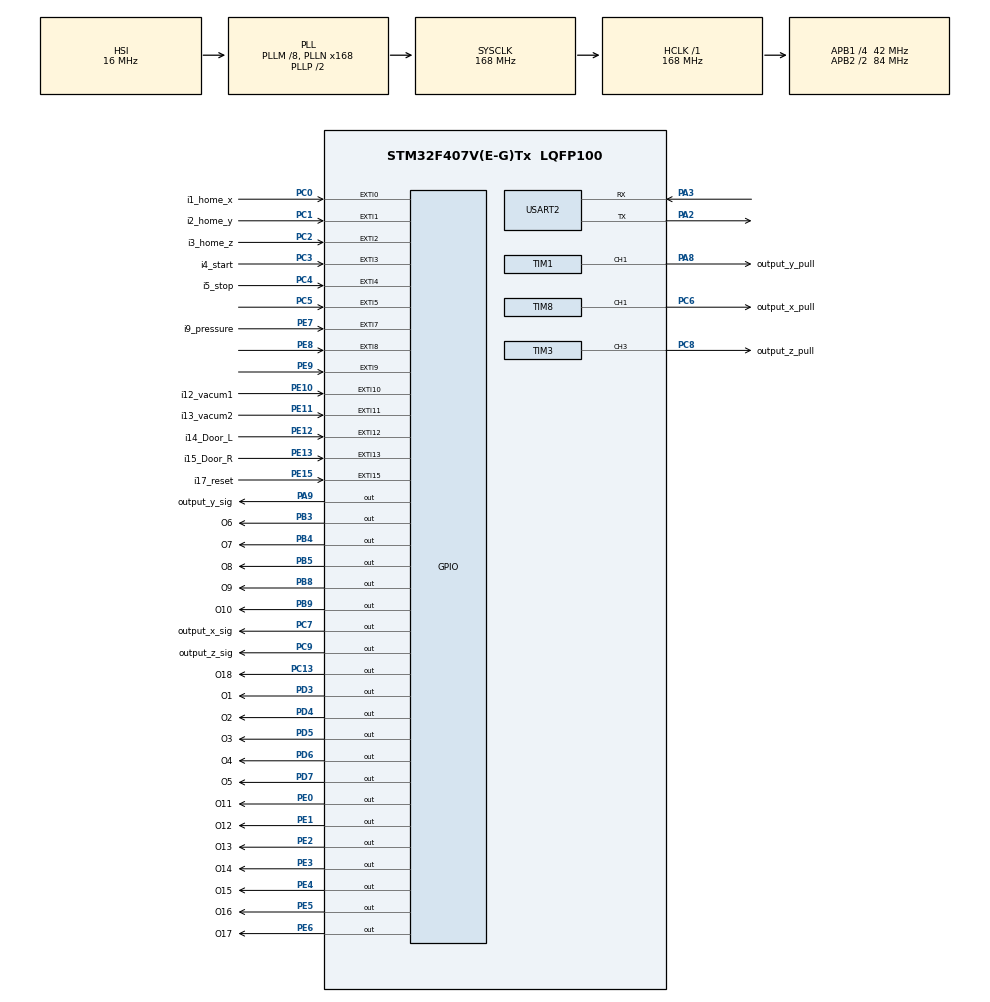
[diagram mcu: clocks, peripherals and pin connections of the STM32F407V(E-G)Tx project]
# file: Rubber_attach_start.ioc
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Dma.Request0=USART2_RX
Dma.USART2_RX.0.Direction=DMA_PERIPH_TO_MEMORY
Dma.USART2_RX.0.FIFOMode=DMA_FIFOMODE_DISABLE
Dma.USART2_RX.0.Instance=DMA1_Stream5
Dma.USART2_RX.0.MemDataAlignment=DMA_MDATAALIGN_BYTE
Dma.USART2_RX.0.MemInc=DMA_MINC_ENABLE
Dma.USART2_RX.0.Mode=DMA_NORMAL
Dma.USART2_RX.0.PeriphDataAlignment=DMA_PDATAALIGN_BYTE
Dma.USART2_RX.0.PeriphInc=DMA_PINC_DISABLE
Dma.USART2_RX.0.Priority=DMA_PRIORITY_LOW
Mcu.Family=STM32F4
Mcu.Name=STM32F407V(E-G)Tx
Mcu.Package=LQFP100
NVIC.DMA1_Stream5_IRQn=true\:0\:0\:false\:false\:true\:false\:true\:true
NVIC.EXTI0_IRQn=true\:10\:0\:true\:false\:true\:true\:true\:true
NVIC.EXTI15_10_IRQn=true\:4\:0\:true\:false\:true\:true\:true\:true
NVIC.EXTI1_IRQn=true\:10\:0\:true\:false\:true\:true\:true\:true
NVIC.EXTI2_IRQn=true\:10\:0\:true\:false\:true\:true\:true\:true
NVIC.EXTI3_IRQn=true\:3\:0\:true\:false\:true\:true\:true\:true
NVIC.EXTI4_IRQn=true\:1\:0\:true\:false\:true\:true\:true\:true
NVIC.EXTI9_5_IRQn=true\:2\:0\:true\:false\:true\:true\:true\:true
NVIC.PriorityGroup=NVIC_PRIORITYGROUP_4
NVIC.TIM1_BRK_TIM9_IRQn=true\:12\:0\:true\:false\:true\:true\:true\:true
NVIC.TIM2_IRQn=true\:12\:0\:true\:false\:true\:true\:true\:true
NVIC.TIM5_IRQn=true\:12\:0\:true\:false\:true\:true\:true\:true
NVIC.TIM6_DAC_IRQn=true\:15\:0\:true\:false\:true\:true\:true\:true
NVIC.TIM7_IRQn=true\:13\:0\:true\:false\:true\:true\:true\:true
NVIC.USART2_IRQn=true\:14\:0\:true\:false\:true\:true\:true\:true
PA13.Mode=Serial_Wire
PA13.Signal=SYS_JTMS-SWDIO
PA14.Mode=Serial_Wire
PA14.Signal=SYS_JTCK-SWCLK
PA2.Mode=Asynchronous
PA2.Signal=USART2_TX
PA3.Mode=Asynchronous
PA3.Signal=USART2_RX
PA8.GPIO_Label=output_y_pull
PA8.GPIO_PuPd=GPIO_PULLDOWN
PA8.GPIO_Speed=GPIO_SPEED_FREQ_VERY_HIGH
PA8.Signal=S_TIM1_CH1
PA9.GPIO_Label=output_y_sig
PA9.Signal=GPIO_Output
PB3.GPIO_Label=O6
PB3.Signal=GPIO_Output
PB4.GPIO_Label=O7
PB4.Signal=GPIO_Output
PB5.GPIO_Label=O8
PB5.Signal=GPIO_Output
PB8.GPIO_Label=O9
PB8.Signal=GPIO_Output
PB9.GPIO_Label=O10
PB9.PinState=GPIO_PIN_SET
PB9.Signal=GPIO_Output
PC0.GPIO_Label=i1_home_x
PC0.Signal=GPXTI0
PC1.GPIO_Label=i2_home_y
PC1.Signal=GPXTI1
PC13-ANTI_TAMP.GPIO_Label=O18
PC13-ANTI_TAMP.Signal=GPIO_Output
PC2.GPIO_Label=i3_home_z
PC2.Signal=GPXTI2
PC3.GPIO_Label=i4_start
PC3.Signal=GPXTI3
PC4.GPIO_Label=i5_stop
PC4.GPIO_ModeDefaultEXTI=GPIO_MODE_IT_RISING
PC4.Signal=GPXTI4
PC5.Signal=GPXTI5
PC6.GPIO_Label=output_x_pull
PC6.GPIO_PuPd=GPIO_PULLDOWN
PC6.GPIO_Speed=GPIO_SPEED_FREQ_VERY_HIGH
PC6.Signal=S_TIM8_CH1
PC7.GPIO_Label=output_x_sig
PC7.Signal=GPIO_Output
PC8.GPIO_Label=output_z_pull
PC8.GPIO_PuPd=GPIO_PULLDOWN
PC8.GPIO_Speed=GPIO_SPEED_FREQ_VERY_HIGH
PC8.Signal=S_TIM3_CH3
PC9.GPIO_Label=output_z_sig
PC9.Signal=GPIO_Output
PD3.GPIO_Label=O1
PD3.Signal=GPIO_Output
PD4.GPIO_Label=O2
PD4.Signal=GPIO_Output
PD5.GPIO_Label=O3
PD5.Signal=GPIO_Output
PD6.GPIO_Label=O4
PD6.Signal=GPIO_Output
PD7.GPIO_Label=O5
PD7.Signal=GPIO_Output
PE0.GPIO_Label=O11
PE0.PinState=GPIO_PIN_SET
PE0.Signal=GPIO_Output
PE1.GPIO_Label=O12
PE1.GPIO_PuPd=GPIO_NOPULL
PE1.PinState=GPIO_PIN_SET
PE1.Signal=GPIO_Output
PE10.GPIO_Label=i12_vacum1
PE10.Signal=GPXTI10
PE11.GPIO_Label=i13_vacum2
PE11.Signal=GPXTI11
PE12.GPIO_Label=i14_Door_L
PE12.GPIO_ModeDefaultEXTI=GPIO_MODE_IT_RISING_FALLING
PE12.Signal=GPXTI12
PE13.GPIO_Label=i15_Door_R
PE13.Signal=GPXTI13
PE15.GPIO_Label=i17_reset
PE15.Signal=GPXTI15
PE2.GPIO_Label=O13
PE2.PinState=GPIO_PIN_SET
PE2.Signal=GPIO_Output
PE3.GPIO_Label=O14
PE3.Signal=GPIO_Output
PE4.GPIO_Label=O15
PE4.Signal=GPIO_Output
PE5.GPIO_Label=O16
PE5.Signal=GPIO_Output
PE6.GPIO_Label=O17
PE6.Signal=GPIO_Output
PE7.GPIO_Label=i9_pressure
PE7.Signal=GPXTI7
PE8.Signal=GPXTI8
PE9.Signal=GPXTI9
PH0-OSC_IN.Mode=HSE-External-Oscillator
PH0-OSC_IN.Signal=RCC_OSC_IN
PH1-OSC_OUT.Mode=HSE-External-Oscillator
PH1-OSC_OUT.Signal=RCC_OSC_OUT
ProjectManager.HeapSize=0x200
ProjectManager.StackSize=0x400
ProjectManager.TargetToolchain=STM32CubeIDE
RCC.48MHZClocksFreq_Value=84000000
RCC.AHBFreq_Value=168000000
RCC.APB1CLKDivider=RCC_HCLK_DIV4
RCC.APB1Freq_Value=42000000
RCC.APB1TimFreq_Value=84000000
RCC.APB2CLKDivider=RCC_HCLK_DIV2
RCC.APB2Freq_Value=84000000
RCC.APB2TimFreq_Value=168000000
RCC.CortexFreq_Value=168000000
RCC.HCLKFreq_Value=168000000
RCC.HSE_VALUE=8000000
RCC.HSI_VALUE=16000000
RCC.LSE_VALUE=32768
RCC.PLLM=8
RCC.PLLN=168
RCC.SYSCLKFreq_VALUE=168000000
RCC.SYSCLKSource=RCC_SYSCLKSOURCE_PLLCLK
RCC.VCOOutputFreq_Value=336000000
SH.S_TIM1_CH1.0=TIM1_CH1,PWM Generation1 CH1
SH.S_TIM3_CH3.0=TIM3_CH3,PWM Generation3 CH3
SH.S_TIM8_CH1.0=TIM8_CH1,PWM Generation1 CH1
TIM1.Channel-PWM\ Generation1\ CH1=TIM_CHANNEL_1
TIM1.OCPolarity_1=TIM_OCPOLARITY_LOW
TIM1.Period=100
TIM1.Prescaler=83
TIM1.Pulse-PWM\ Generation1\ CH1=50
TIM1.TIM_MasterOutputTrigger=TIM_TRGO_OC1REF
TIM3.Channel-PWM\ Generation3\ CH3=TIM_CHANNEL_3
TIM3.OCPolarity_3=TIM_OCPOLARITY_LOW
TIM3.Period=100
TIM3.Prescaler=41
TIM3.Pulse-PWM\ Generation3\ CH3=50
TIM3.TIM_MasterOutputTrigger=TIM_TRGO_OC3REF
TIM5.AutoReloadPreload=TIM_AUTORELOAD_PRELOAD_DISABLE
TIM5.Period=4294967295
TIM5.Prescaler=0
TIM5.TIM_MasterOutputTrigger=TIM_TRGO_RESET
TIM6.Period=10000
TIM6.Prescaler=83
TIM7.Period=1000
TIM7.Prescaler=83
TIM8.AutoReloadPreload=TIM_AUTORELOAD_PRELOAD_DISABLE
TIM8.Channel-PWM\ Generation1\ CH1=TIM_CHANNEL_1
TIM8.OCPolarity_1=TIM_OCPOLARITY_LOW
TIM8.Period=100
TIM8.Prescaler=83
TIM8.Pulse-PWM\ Generation1\ CH1=50
TIM8.TIM_MasterOutputTrigger=TIM_TRGO_OC1REF
USART2.VirtualMode=VM_ASYNC
VP_TIM2_VS_ClockSourceITR.Mode=TriggerSource_ITR0
VP_TIM2_VS_ControllerModeClock.Mode=Clock Mode
VP_TIM5_VS_ClockSourceITR.Mode=TriggerSource_ITR3
VP_TIM5_VS_ControllerModeClock.Mode=Clock Mode
VP_TIM6_VS_ClockSourceINT.Mode=Enable_Timer
VP_TIM7_VS_ClockSourceINT.Mode=Enable_Timer
VP_TIM9_VS_ClockSourceITR.Mode=TriggerSource_ITR1
VP_TIM9_VS_ControllerModeClock.Mode=Clock Mode
board=custom

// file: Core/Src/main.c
/* USER CODE BEGIN Header */
/**
  ******************************************************************************
  * @file           : main.c
  * @brief          : Main program body
  ******************************************************************************
  * @attention
  *
  * Copyright (c) 2025 STMicroelectronics.
  * All rights reserved.
  *
  * This software is licensed under terms that can be found in the LICENSE file
  * in the root directory of this software component.
  * If no LICENSE file comes with this software, it is provided AS-IS.
  *
  ******************************************************************************
  */
/* USER CODE END Header */
#include "main.h"

/* USER CODE BEGIN Includes */
//#include "stm32f4xx_ll_tim.h"
#include "application.h"
/* USER CODE END Includes */

TIM_HandleTypeDef htim1;
TIM_HandleTypeDef htim2;
TIM_HandleTypeDef htim3;
TIM_HandleTypeDef htim5;
TIM_HandleTypeDef htim6;
TIM_HandleTypeDef htim7;
TIM_HandleTypeDef htim8;
TIM_HandleTypeDef htim9;

UART_HandleTypeDef huart2;
DMA_HandleTypeDef hdma_usart2_rx;

void SystemClock_Config(void);
static void MX_GPIO_Init(void);
static void MX_DMA_Init(void);
static void MX_USART2_UART_Init(void);
static void MX_TIM5_Init(void);
static void MX_TIM8_Init(void);
static void MX_TIM1_Init(void);
static void MX_TIM2_Init(void);
static void MX_TIM3_Init(void);
static void MX_TIM9_Init(void);
static void MX_TIM6_Init(void);
static void MX_TIM7_Init(void);

int main(void)
{

  /* MCU Configuration--------------------------------------------------------*/

  /* Reset of all peripherals, Initializes the Flash interface and the Systick. */
  HAL_Init();

  /* Configure the system clock */
  SystemClock_Config();

  /* Initialize all configured peripherals */
  MX_GPIO_Init();
  MX_DMA_Init();
  MX_USART2_UART_Init();
  MX_TIM5_Init();
  MX_TIM8_Init();
  MX_TIM1_Init();
  MX_TIM2_Init();
  MX_TIM3_Init();
  MX_TIM9_Init();
  MX_TIM6_Init();
  MX_TIM7_Init();
  /* USER CODE BEGIN 2 */
  application_init();

  /* USER CODE END 2 */

  /* Infinite loop */
  while (1)
  {

    /* USER CODE BEGIN 3 */
	  application_run_main();
  }
  /* USER CODE END 3 */
}

void SystemClock_Config(void)
{
  RCC_OscInitTypeDef RCC_OscInitStruct = {0};
  RCC_ClkInitTypeDef RCC_ClkInitStruct = {0};

  /** Configure the main internal regulator output voltage
  */
  __HAL_RCC_PWR_CLK_ENABLE();
  __HAL_PWR_VOLTAGESCALING_CONFIG(PWR_REGULATOR_VOLTAGE_SCALE1);

  /** Initializes the RCC Oscillators according to the specified parameters
  * in the RCC_OscInitTypeDef structure.
  */
  RCC_OscInitStruct.OscillatorType = RCC_OSCILLATORTYPE_HSI;
  RCC_OscInitStruct.HSIState = RCC_HSI_ON;
  RCC_OscInitStruct.HSICalibrationValue = RCC_HSICALIBRATION_DEFAULT;
  RCC_OscInitStruct.PLL.PLLState = RCC_PLL_ON;
  RCC_OscInitStruct.PLL.PLLSource = RCC_PLLSOURCE_HSI;
  RCC_OscInitStruct.PLL.PLLM = 8;
  RCC_OscInitStruct.PLL.PLLN = 168;
  RCC_OscInitStruct.PLL.PLLP = RCC_PLLP_DIV2;
  RCC_OscInitStruct.PLL.PLLQ = 4;
  if (HAL_RCC_OscConfig(&RCC_OscInitStruct) != HAL_OK)
  {
    Error_Handler();
  }

  /** Initializes the CPU, AHB and APB buses clocks
  */
  RCC_ClkInitStruct.ClockType = RCC_CLOCKTYPE_HCLK|RCC_CLOCKTYPE_SYSCLK
                              |RCC_CLOCKTYPE_PCLK1|RCC_CLOCKTYPE_PCLK2;
  RCC_ClkInitStruct.SYSCLKSource = RCC_SYSCLKSOURCE_PLLCLK;
  RCC_ClkInitStruct.AHBCLKDivider = RCC_SYSCLK_DIV1;
  RCC_ClkInitStruct.APB1CLKDivider = RCC_HCLK_DIV4;
  RCC_ClkInitStruct.APB2CLKDivider = RCC_HCLK_DIV2;

  if (HAL_RCC_ClockConfig(&RCC_ClkInitStruct, FLASH_LATENCY_5) != HAL_OK)
  {
    Error_Handler();
  }
}

static void MX_TIM1_Init(void)
{

  TIM_MasterConfigTypeDef sMasterConfig = {0};
  TIM_OC_InitTypeDef sConfigOC = {0};
  TIM_BreakDeadTimeConfigTypeDef sBreakDeadTimeConfig = {0};

  htim1.Instance = TIM1;
  htim1.Init.Prescaler = 83;
  htim1.Init.CounterMode = TIM_COUNTERMODE_UP;
  htim1.Init.Period = 100;
  htim1.Init.ClockDivision = TIM_CLOCKDIVISION_DIV1;
  htim1.Init.RepetitionCounter = 0;
  htim1.Init.AutoReloadPreload = TIM_AUTORELOAD_PRELOAD_DISABLE;
  if (HAL_TIM_PWM_Init(&htim1) != HAL_OK)
  {
    Error_Handler();
  }
  sMasterConfig.MasterOutputTrigger = TIM_TRGO_OC1REF;
  sMasterConfig.MasterSlaveMode = TIM_MASTERSLAVEMODE_DISABLE;
  if (HAL_TIMEx_MasterConfigSynchronization(&htim1, &sMasterConfig) != HAL_OK)
  {
    Error_Handler();
  }
  sConfigOC.OCMode = TIM_OCMODE_PWM1;
  sConfigOC.Pulse = 50;
  sConfigOC.OCPolarity = TIM_OCPOLARITY_LOW;
  sConfigOC.OCNPolarity = TIM_OCNPOLARITY_HIGH;
  sConfigOC.OCFastMode = TIM_OCFAST_DISABLE;
  sConfigOC.OCIdleState = TIM_OCIDLESTATE_RESET;
  sConfigOC.OCNIdleState = TIM_OCNIDLESTATE_RESET;
  if (HAL_TIM_PWM_ConfigChannel(&htim1, &sConfigOC, TIM_CHANNEL_1) != HAL_OK)
  {
    Error_Handler();
  }
  sBreakDeadTimeConfig.OffStateRunMode = TIM_OSSR_DISABLE;
  sBreakDeadTimeConfig.OffStateIDLEMode = TIM_OSSI_DISABLE;
  sBreakDeadTimeConfig.LockLevel = TIM_LOCKLEVEL_OFF;
  sBreakDeadTimeConfig.DeadTime = 0;
  sBreakDeadTimeConfig.BreakState = TIM_BREAK_DISABLE;
  sBreakDeadTimeConfig.BreakPolarity = TIM_BREAKPOLARITY_HIGH;
  sBreakDeadTimeConfig.AutomaticOutput = TIM_AUTOMATICOUTPUT_DISABLE;
  if (HAL_TIMEx_ConfigBreakDeadTime(&htim1, &sBreakDeadTimeConfig) != HAL_OK)
  {
    Error_Handler();
  }
  HAL_TIM_MspPostInit(&htim1);

}

static void MX_TIM2_Init(void)
{

  TIM_SlaveConfigTypeDef sSlaveConfig = {0};
  TIM_MasterConfigTypeDef sMasterConfig = {0};

  htim2.Instance = TIM2;
  htim2.Init.Prescaler = 0;
  htim2.Init.CounterMode = TIM_COUNTERMODE_UP;
  htim2.Init.Period = 4294967295;
  htim2.Init.ClockDivision = TIM_CLOCKDIVISION_DIV1;
  htim2.Init.AutoReloadPreload = TIM_AUTORELOAD_PRELOAD_DISABLE;
  if (HAL_TIM_Base_Init(&htim2) != HAL_OK)
  {
    Error_Handler();
  }
  sSlaveConfig.SlaveMode = TIM_SLAVEMODE_EXTERNAL1;
  sSlaveConfig.InputTrigger = TIM_TS_ITR0;
  if (HAL_TIM_SlaveConfigSynchro(&htim2, &sSlaveConfig) != HAL_OK)
  {
    Error_Handler();
  }
  sMasterConfig.MasterOutputTrigger = TIM_TRGO_RESET;
  sMasterConfig.MasterSlaveMode = TIM_MASTERSLAVEMODE_DISABLE;
  if (HAL_TIMEx_MasterConfigSynchronization(&htim2, &sMasterConfig) != HAL_OK)
  {
    Error_Handler();
  }

}

static void MX_TIM3_Init(void)
{

  TIM_MasterConfigTypeDef sMasterConfig = {0};
  TIM_OC_InitTypeDef sConfigOC = {0};

  htim3.Instance = TIM3;
  htim3.Init.Prescaler = 41;
  htim3.Init.CounterMode = TIM_COUNTERMODE_UP;
  htim3.Init.Period = 100;
  htim3.Init.ClockDivision = TIM_CLOCKDIVISION_DIV1;
  htim3.Init.AutoReloadPreload = TIM_AUTORELOAD_PRELOAD_DISABLE;
  if (HAL_TIM_PWM_Init(&htim3) != HAL_OK)
  {
    Error_Handler();
  }
  sMasterConfig.MasterOutputTrigger = TIM_TRGO_OC3REF;
  sMasterConfig.MasterSlaveMode = TIM_MASTERSLAVEMODE_DISABLE;
  if (HAL_TIMEx_MasterConfigSynchronization(&htim3, &sMasterConfig) != HAL_OK)
  {
    Error_Handler();
  }
  sConfigOC.OCMode = TIM_OCMODE_PWM1;
  sConfigOC.Pulse = 50;
  sConfigOC.OCPolarity = TIM_OCPOLARITY_LOW;
  sConfigOC.OCFastMode = TIM_OCFAST_DISABLE;
  if (HAL_TIM_PWM_ConfigChannel(&htim3, &sConfigOC, TIM_CHANNEL_3) != HAL_OK)
  {
    Error_Handler();
  }
  HAL_TIM_MspPostInit(&htim3);

}

static void MX_TIM5_Init(void)
{

  TIM_SlaveConfigTypeDef sSlaveConfig = {0};
  TIM_MasterConfigTypeDef sMasterConfig = {0};

  htim5.Instance = TIM5;
  htim5.Init.Prescaler = 0;
  htim5.Init.CounterMode = TIM_COUNTERMODE_UP;
  htim5.Init.Period = 4294967295;
  htim5.Init.ClockDivision = TIM_CLOCKDIVISION_DIV1;
  htim5.Init.AutoReloadPreload = TIM_AUTORELOAD_PRELOAD_DISABLE;
  if (HAL_TIM_Base_Init(&htim5) != HAL_OK)
  {
    Error_Handler();
  }
  sSlaveConfig.SlaveMode = TIM_SLAVEMODE_EXTERNAL1;
  sSlaveConfig.InputTrigger = TIM_TS_ITR3;
  if (HAL_TIM_SlaveConfigSynchro(&htim5, &sSlaveConfig) != HAL_OK)
  {
    Error_Handler();
  }
  sMasterConfig.MasterOutputTrigger = TIM_TRGO_RESET;
  sMasterConfig.MasterSlaveMode = TIM_MASTERSLAVEMODE_DISABLE;
  if (HAL_TIMEx_MasterConfigSynchronization(&htim5, &sMasterConfig) != HAL_OK)
  {
    Error_Handler();
  }

}

static void MX_TIM6_Init(void)
{

  TIM_MasterConfigTypeDef sMasterConfig = {0};

  htim6.Instance = TIM6;
  htim6.Init.Prescaler = 83;
  htim6.Init.CounterMode = TIM_COUNTERMODE_UP;
  htim6.Init.Period = 10000;
  htim6.Init.AutoReloadPreload = TIM_AUTORELOAD_PRELOAD_DISABLE;
  if (HAL_TIM_Base_Init(&htim6) != HAL_OK)
  {
    Error_Handler();
  }
  sMasterConfig.MasterOutputTrigger = TIM_TRGO_RESET;
  sMasterConfig.MasterSlaveMode = TIM_MASTERSLAVEMODE_DISABLE;
  if (HAL_TIMEx_MasterConfigSynchronization(&htim6, &sMasterConfig) != HAL_OK)
  {
    Error_Handler();
  }

}

static void MX_TIM7_Init(void)
{

  TIM_MasterConfigTypeDef sMasterConfig = {0};

  htim7.Instance = TIM7;
  htim7.Init.Prescaler = 83;
  htim7.Init.CounterMode = TIM_COUNTERMODE_UP;
  htim7.Init.Period = 1000;
  htim7.Init.AutoReloadPreload = TIM_AUTORELOAD_PRELOAD_DISABLE;
  if (HAL_TIM_Base_Init(&htim7) != HAL_OK)
  {
    Error_Handler();
  }
  sMasterConfig.MasterOutputTrigger = TIM_TRGO_RESET;
  sMasterConfig.MasterSlaveMode = TIM_MASTERSLAVEMODE_DISABLE;
  if (HAL_TIMEx_MasterConfigSynchronization(&htim7, &sMasterConfig) != HAL_OK)
  {
    Error_Handler();
  }

}

static void MX_TIM8_Init(void)
{

  TIM_MasterConfigTypeDef sMasterConfig = {0};
  TIM_OC_InitTypeDef sConfigOC = {0};
  TIM_BreakDeadTimeConfigTypeDef sBreakDeadTimeConfig = {0};

  htim8.Instance = TIM8;
  htim8.Init.Prescaler = 83;
  htim8.Init.CounterMode = TIM_COUNTERMODE_UP;
  htim8.Init.Period = 100;
  htim8.Init.ClockDivision = TIM_CLOCKDIVISION_DIV1;
  htim8.Init.RepetitionCounter = 0;
  htim8.Init.AutoReloadPreload = TIM_AUTORELOAD_PRELOAD_DISABLE;
  if (HAL_TIM_PWM_Init(&htim8) != HAL_OK)
  {
    Error_Handler();
  }
  sMasterConfig.MasterOutputTrigger = TIM_TRGO_OC1REF;
  sMasterConfig.MasterSlaveMode = TIM_MASTERSLAVEMODE_DISABLE;
  if (HAL_TIMEx_MasterConfigSynchronization(&htim8, &sMasterConfig) != HAL_OK)
  {
    Error_Handler();
  }
  sConfigOC.OCMode = TIM_OCMODE_PWM1;
  sConfigOC.Pulse = 50;
  sConfigOC.OCPolarity = TIM_OCPOLARITY_LOW;
  sConfigOC.OCNPolarity = TIM_OCNPOLARITY_HIGH;
  sConfigOC.OCFastMode = TIM_OCFAST_DISABLE;
  sConfigOC.OCIdleState = TIM_OCIDLESTATE_RESET;
  sConfigOC.OCNIdleState = TIM_OCNIDLESTATE_RESET;
  if (HAL_TIM_PWM_ConfigChannel(&htim8, &sConfigOC, TIM_CHANNEL_1) != HAL_OK)
  {
    Error_Handler();
  }
  sBreakDeadTimeConfig.OffStateRunMode = TIM_OSSR_DISABLE;
  sBreakDeadTimeConfig.OffStateIDLEMode = TIM_OSSI_DISABLE;
  sBreakDeadTimeConfig.LockLevel = TIM_LOCKLEVEL_OFF;
  sBreakDeadTimeConfig.DeadTime = 0;
  sBreakDeadTimeConfig.BreakState = TIM_BREAK_DISABLE;
  sBreakDeadTimeConfig.BreakPolarity = TIM_BREAKPOLARITY_HIGH;
  sBreakDeadTimeConfig.AutomaticOutput = TIM_AUTOMATICOUTPUT_DISABLE;
  if (HAL_TIMEx_ConfigBreakDeadTime(&htim8, &sBreakDeadTimeConfig) != HAL_OK)
  {
    Error_Handler();
  }
  HAL_TIM_MspPostInit(&htim8);

}

static void MX_TIM9_Init(void)
{

  TIM_SlaveConfigTypeDef sSlaveConfig = {0};

  htim9.Instance = TIM9;
  htim9.Init.Prescaler = 0;
  htim9.Init.CounterMode = TIM_COUNTERMODE_UP;
  htim9.Init.Period = 65535;
  htim9.Init.ClockDivision = TIM_CLOCKDIVISION_DIV1;
  htim9.Init.AutoReloadPreload = TIM_AUTORELOAD_PRELOAD_DISABLE;
  if (HAL_TIM_Base_Init(&htim9) != HAL_OK)
  {
    Error_Handler();
  }
  sSlaveConfig.SlaveMode = TIM_SLAVEMODE_EXTERNAL1;
  sSlaveConfig.InputTrigger = TIM_TS_ITR1;
  if (HAL_TIM_SlaveConfigSynchro(&htim9, &sSlaveConfig) != HAL_OK)
  {
    Error_Handler();
  }

}

static void MX_USART2_UART_Init(void)
{

  huart2.Instance = USART2;
  huart2.Init.BaudRate = 115200;
  huart2.Init.WordLength = UART_WORDLENGTH_8B;
  huart2.Init.StopBits = UART_STOPBITS_1;
  huart2.Init.Parity = UART_PARITY_NONE;
  huart2.Init.Mode = UART_MODE_TX_RX;
  huart2.Init.HwFlowCtl = UART_HWCONTROL_NONE;
  huart2.Init.OverSampling = UART_OVERSAMPLING_16;
  if (HAL_UART_Init(&huart2) != HAL_OK)
  {
    Error_Handler();
  }

}

static void MX_DMA_Init(void)
{

  /* DMA controller clock enable */
  __HAL_RCC_DMA1_CLK_ENABLE();

  /* DMA interrupt init */
  /* DMA1_Stream5_IRQn interrupt configuration */
  HAL_NVIC_SetPriority(DMA1_Stream5_IRQn, 0, 0);
  HAL_NVIC_EnableIRQ(DMA1_Stream5_IRQn);

}

static void MX_GPIO_Init(void)
{
  GPIO_InitTypeDef GPIO_InitStruct = {0};

  /* GPIO Ports Clock Enable */
  __HAL_RCC_GPIOE_CLK_ENABLE();
  __HAL_RCC_GPIOC_CLK_ENABLE();
  __HAL_RCC_GPIOH_CLK_ENABLE();
  __HAL_RCC_GPIOA_CLK_ENABLE();
  __HAL_RCC_GPIOD_CLK_ENABLE();
  __HAL_RCC_GPIOB_CLK_ENABLE();

  /*Configure GPIO pin Output Level */
  HAL_GPIO_WritePin(GPIOE, O13_Pin|O11_Pin|O12_Pin, GPIO_PIN_SET);

  /*Configure GPIO pin Output Level */
  HAL_GPIO_WritePin(GPIOE, O14_Pin|O15_Pin|O16_Pin|O17_Pin, GPIO_PIN_RESET);

  /*Configure GPIO pin Output Level */
  HAL_GPIO_WritePin(GPIOC, O18_Pin|output_x_sig_Pin|output_z_sig_Pin, GPIO_PIN_RESET);

  /*Configure GPIO pin Output Level */
  HAL_GPIO_WritePin(output_y_sig_GPIO_Port, output_y_sig_Pin, GPIO_PIN_RESET);

  /*Configure GPIO pin Output Level */
  HAL_GPIO_WritePin(GPIOD, O1_Pin|O2_Pin|O3_Pin|O4_Pin
                          |O5_Pin, GPIO_PIN_RESET);

  /*Configure GPIO pin Output Level */
  HAL_GPIO_WritePin(GPIOB, O6_Pin|O7_Pin|O8_Pin|O9_Pin, GPIO_PIN_RESET);

  /*Configure GPIO pin Output Level */
  HAL_GPIO_WritePin(O10_GPIO_Port, O10_Pin, GPIO_PIN_SET);

  /*Configure GPIO pins : O13_Pin O14_Pin O15_Pin O16_Pin
                           O17_Pin O11_Pin O12_Pin */
  GPIO_InitStruct.Pin = O13_Pin|O14_Pin|O15_Pin|O16_Pin
                          |O17_Pin|O11_Pin|O12_Pin;
  GPIO_InitStruct.Mode = GPIO_MODE_OUTPUT_PP;
  GPIO_InitStruct.Pull = GPIO_NOPULL;
  GPIO_InitStruct.Speed = GPIO_SPEED_FREQ_LOW;
  HAL_GPIO_Init(GPIOE, &GPIO_InitStruct);

  /*Configure GPIO pins : O18_Pin output_x_sig_Pin output_z_sig_Pin */
  GPIO_InitStruct.Pin = O18_Pin|output_x_sig_Pin|output_z_sig_Pin;
  GPIO_InitStruct.Mode = GPIO_MODE_OUTPUT_PP;
  GPIO_InitStruct.Pull = GPIO_NOPULL;
  GPIO_InitStruct.Speed = GPIO_SPEED_FREQ_LOW;
  HAL_GPIO_Init(GPIOC, &GPIO_InitStruct);

  /*Configure GPIO pins : i1_home_x_Pin i2_home_y_Pin i3_home_z_Pin i4_start_Pin
                           i5_stop_Pin PC5 */
  GPIO_InitStruct.Pin = i1_home_x_Pin|i2_home_y_Pin|i3_home_z_Pin|i4_start_Pin
                          |i5_stop_Pin|GPIO_PIN_5;
  GPIO_InitStruct.Mode = GPIO_MODE_IT_RISING;
  GPIO_InitStruct.Pull = GPIO_NOPULL;
  HAL_GPIO_Init(GPIOC, &GPIO_InitStruct);

  /*Configure GPIO pins : i9_pressure_Pin PE8 PE9 i12_vacum1_Pin
                           i13_vacum2_Pin i15_Door_R_Pin i17_reset_Pin */
  GPIO_InitStruct.Pin = i9_pressure_Pin|GPIO_PIN_8|GPIO_PIN_9|i12_vacum1_Pin
                          |i13_vacum2_Pin|i15_Door_R_Pin|i17_reset_Pin;
  GPIO_InitStruct.Mode = GPIO_MODE_IT_RISING;
  GPIO_InitStruct.Pull = GPIO_NOPULL;
  HAL_GPIO_Init(GPIOE, &GPIO_InitStruct);

  /*Configure GPIO pin : i14_Door_L_Pin */
  GPIO_InitStruct.Pin = i14_Door_L_Pin;
  GPIO_InitStruct.Mode = GPIO_MODE_IT_RISING_FALLING;
  GPIO_InitStruct.Pull = GPIO_NOPULL;
  HAL_GPIO_Init(i14_Door_L_GPIO_Port, &GPIO_InitStruct);

  /*Configure GPIO pin : output_y_sig_Pin */
  GPIO_InitStruct.Pin = output_y_sig_Pin;
  GPIO_InitStruct.Mode = GPIO_MODE_OUTPUT_PP;
  GPIO_InitStruct.Pull = GPIO_NOPULL;
  GPIO_InitStruct.Speed = GPIO_SPEED_FREQ_LOW;
  HAL_GPIO_Init(output_y_sig_GPIO_Port, &GPIO_InitStruct);

  /*Configure GPIO pins : O1_Pin O2_Pin O3_Pin O4_Pin
                           O5_Pin */
  GPIO_InitStruct.Pin = O1_Pin|O2_Pin|O3_Pin|O4_Pin
                          |O5_Pin;
  GPIO_InitStruct.Mode = GPIO_MODE_OUTPUT_PP;
  GPIO_InitStruct.Pull = GPIO_NOPULL;
  GPIO_InitStruct.Speed = GPIO_SPEED_FREQ_LOW;
  HAL_GPIO_Init(GPIOD, &GPIO_InitStruct);

  /*Configure GPIO pins : O6_Pin O7_Pin O8_Pin O9_Pin
                           O10_Pin */
  GPIO_InitStruct.Pin = O6_Pin|O7_Pin|O8_Pin|O9_Pin
                          |O10_Pin;
  GPIO_InitStruct.Mode = GPIO_MODE_OUTPUT_PP;
  GPIO_InitStruct.Pull = GPIO_NOPULL;
  GPIO_InitStruct.Speed = GPIO_SPEED_FREQ_LOW;
  HAL_GPIO_Init(GPIOB, &GPIO_InitStruct);

  /* EXTI interrupt init*/
  HAL_NVIC_SetPriority(EXTI0_IRQn, 10, 0);
  HAL_NVIC_EnableIRQ(EXTI0_IRQn);

  HAL_NVIC_SetPriority(EXTI1_IRQn, 10, 0);
  HAL_NVIC_EnableIRQ(EXTI1_IRQn);

  HAL_NVIC_SetPriority(EXTI2_IRQn, 10, 0);
  HAL_NVIC_EnableIRQ(EXTI2_IRQn);

  HAL_NVIC_SetPriority(EXTI3_IRQn, 3, 0);
  HAL_NVIC_EnableIRQ(EXTI3_IRQn);

  HAL_NVIC_SetPriority(EXTI4_IRQn, 1, 0);
  HAL_NVIC_EnableIRQ(EXTI4_IRQn);

  HAL_NVIC_SetPriority(EXTI9_5_IRQn, 2, 0);
  HAL_NVIC_EnableIRQ(EXTI9_5_IRQn);

  HAL_NVIC_SetPriority(EXTI15_10_IRQn, 4, 0);
  HAL_NVIC_EnableIRQ(EXTI15_10_IRQn);

}

void Error_Handler(void)
{
  __disable_irq();
  while (1)
  {
  }
}
